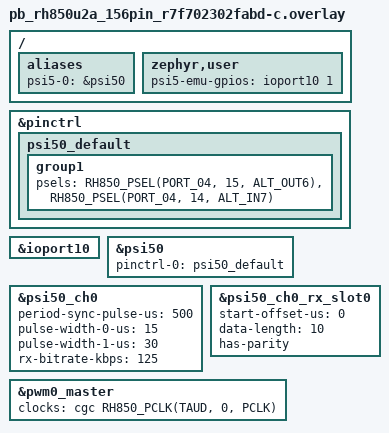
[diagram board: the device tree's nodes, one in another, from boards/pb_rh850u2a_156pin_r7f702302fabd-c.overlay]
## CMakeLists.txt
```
# SPDX-License-Identifier: Apache-2.0

cmake_minimum_required(VERSION 3.20.0)
find_package(Zephyr REQUIRED HINTS $ENV{ZEPHYR_BASE})
project(psi5_rx)

target_sources(app PRIVATE
  src/main.c
  src/psi5_emu.c
)
```

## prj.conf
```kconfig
CONFIG_ZTEST=y
CONFIG_PSI5=y
CONFIG_GPIO=y
CONFIG_LOG=y
```

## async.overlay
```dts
/*
 * Copyright (c) 2026 Renesas Electronics Corporation
 *
 * SPDX-License-Identifier: Apache-2.0
 */

/*
 * Scenario drivers.psi5.rx.async.data_frame (T22):
 * PSI5-A asynchronous mode on the test channel (no sync pulse, no TX).
 * Applied on top of boards/<board>.overlay via EXTRA_DTC_OVERLAY_FILE (testcase.yaml).
 * Driver: started in init (CHEN = 1), start_sync/stop_sync/send -> -ENOTSUP, slot@0 only.
 */
&psi50_ch0 {
	async-mode;
};
```

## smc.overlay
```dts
/*
 * Copyright (c) 2026 Renesas Electronics Corporation
 *
 * SPDX-License-Identifier: Apache-2.0
 */

/*
 * Enable serial message reception on the first RX slot.
 */
&psi50_ch0_rx_slot0 {
	has-smc;
};
```

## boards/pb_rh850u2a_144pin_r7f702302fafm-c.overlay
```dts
/*
 * Copyright (c) 2026 Renesas Electronics Corporation
 * SPDX-License-Identifier: Apache-2.0
 */

#include <zephyr/dt-bindings/gpio/gpio.h>

/ {
	aliases {
		psi5-0 = &psi50;
	};

	zephyr,user {
		psi5-emu-gpios = <&ioport10 1 GPIO_ACTIVE_HIGH>;
	};
};

&pinctrl {
	psi50_default: psi50_default {
		group1 {
			psels = <RH850_PSEL(PORT_04, 15, ALT_OUT6)>,
				<RH850_PSEL(PORT_04, 14, ALT_IN7)>;
		};
	};
};

&ioport10 {
	status = "okay";
};

&psi50 {
	pinctrl-0 = <&psi50_default>;
	pinctrl-names = "default";
	status = "okay";
};

&psi50_ch0 {
	period-sync-pulse-us = <500>;
	pulse-width-0-us = <15>;
	pulse-width-1-us = <30>;
	rx-bitrate-kbps = <125>;
	status = "okay";
};

&psi50_ch0_rx_slot0 {
	start-offset-us = <0>;
	data-length = <10>;
	has-parity;
	status = "okay";
};
```

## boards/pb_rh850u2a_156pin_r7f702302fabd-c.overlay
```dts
/*
 * Copyright (c) 2026 Renesas Electronics Corporation
 * SPDX-License-Identifier: Apache-2.0
 */

#include <zephyr/dt-bindings/gpio/gpio.h>

/ {
	aliases {
		psi5-0 = &psi50;
	};

	zephyr,user {
		psi5-emu-gpios = <&ioport10 1 GPIO_ACTIVE_HIGH>;
	};
};

&pinctrl {
	psi50_default: psi50_default {
		group1 {
			psels = <RH850_PSEL(PORT_04, 15, ALT_OUT6)>,
				<RH850_PSEL(PORT_04, 14, ALT_IN7)>;
		};
	};
};

&ioport10 {
	status = "okay";
};

&psi50 {
	pinctrl-0 = <&psi50_default>;
	pinctrl-names = "default";
	status = "okay";
};

&psi50_ch0 {
	period-sync-pulse-us = <500>;
	pulse-width-0-us = <15>;
	pulse-width-1-us = <30>;
	rx-bitrate-kbps = <125>;
	status = "okay";
};

&psi50_ch0_rx_slot0 {
	start-offset-us = <0>;
	data-length = <10>;
	has-parity;
	status = "okay";
};

&pwm0_master {
	clocks = <&cgc RH850_PCLK(TAUD, 0, PCLK)>;
	status = "okay";
};
```

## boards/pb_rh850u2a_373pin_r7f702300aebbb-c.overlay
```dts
/*
 * Copyright (c) 2026 Renesas Electronics Corporation
 * SPDX-License-Identifier: Apache-2.0
 */

#include <zephyr/dt-bindings/gpio/gpio.h>

/ {
	aliases {
		psi5-0 = &psi50;
	};

	zephyr,user {
		psi5-emu-gpios = <&ioport22 0 GPIO_ACTIVE_HIGH>;
	};
};

&pinctrl {
	psi50_default: psi50_default {
		group1 {
			psels = <RH850_PSEL(PORT_04, 15, ALT_OUT6)>,
				<RH850_PSEL(PORT_04, 14, ALT_IN7)>;
		};
	};
};

&ioport22 {
	status = "okay";
};

&psi50 {
	pinctrl-0 = <&psi50_default>;
	pinctrl-names = "default";
	status = "okay";
};

&psi50_ch0 {
	period-sync-pulse-us = <500>;
	pulse-width-0-us = <15>;
	pulse-width-1-us = <30>;
	rx-bitrate-kbps = <125>;
	status = "okay";
};

&psi50_ch0_rx_slot0 {
	start-offset-us = <0>;
	data-length = <10>;
	has-parity;
	status = "okay";
};

&pwm0_master {
	clocks = <&cgc RH850_PCLK(TAUD, 0, PCLK)>;
	status = "okay";
};
```

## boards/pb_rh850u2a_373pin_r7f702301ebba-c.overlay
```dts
/*
 * Copyright (c) 2026 Renesas Electronics Corporation
 * SPDX-License-Identifier: Apache-2.0
 */

#include <zephyr/dt-bindings/gpio/gpio.h>

/ {
	aliases {
		psi5-0 = &psi50;
	};

	zephyr,user {
		psi5-emu-gpios = <&ioport22 0 GPIO_ACTIVE_HIGH>;
	};
};

&pinctrl {
	psi50_default: psi50_default {
		group1 {
			psels = <RH850_PSEL(PORT_04, 15, ALT_OUT6)>,
				<RH850_PSEL(PORT_04, 14, ALT_IN7)>;
		};
	};
};

&ioport22 {
	status = "okay";
};

&psi50 {
	pinctrl-0 = <&psi50_default>;
	pinctrl-names = "default";
	status = "okay";
};

&psi50_ch0 {
	period-sync-pulse-us = <500>;
	pulse-width-0-us = <15>;
	pulse-width-1-us = <30>;
	rx-bitrate-kbps = <125>;
	status = "okay";
};

&psi50_ch0_rx_slot0 {
	start-offset-us = <0>;
	data-length = <10>;
	has-parity;
	status = "okay";
};
```

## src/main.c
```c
/*
 * Copyright (c) 2026 Renesas Electronics Corporation
 *
 * SPDX-License-Identifier: Apache-2.0
 */

#include <errno.h>
#include <stdbool.h>
#include <stdint.h>

#include <zephyr/device.h>
#include <zephyr/drivers/psi5/psi5.h>
#include <zephyr/kernel.h>
#include <zephyr/ztest.h>

#define PSI5_NODE          DT_ALIAS(psi5_0)
#define PSI5_CHANNEL       0U
#define PSI5_MAX_RX_BUFFER 1U
#define PSI5_RX_TIMEOUT    K_MSEC(100)
#define PSI5_NO_CB_WINDOW  K_MSEC(20)
#define PSI5_TX_TIMEOUT    K_MSEC(200)
#define PSI5_STOP_TIMEOUT  K_MSEC(200)

#define PSI5_EMU_DATA            0x1E7U
#define PSI5_EMU_RESTART_DATA    0x0ABU
#define PSI5_EMU_DATA_LEN        10U
#define PSI5_EMU_BAD_PARITY_DATA (0x3F3U | BIT(PSI5_EMU_DATA_LEN))
#define PSI5_EMU_BAD_PARITY_LEN  (PSI5_EMU_DATA_LEN + 1U)
#define PSI5_EMU_SMC_RESET_DATA  0x0F0U
#define PSI5_EMU_SMC_CRC         0x20U
#define PSI5_SMC_EXP_ID          0x55U
#define PSI5_SMC_EXP_DATA        0x3E1U
#define PSI5_SMC_TIMEOUT         K_MSEC(100)

#define PSI5_TX_DATA_FIT     0x3FU
#define PSI5_TX_DATA_OVER    0x40U
#define PSI5_TX_DATA_OVER_HI UINT64_C(0x100000000)

#define PSI5_SMC_SLOT_NODE DT_NODELABEL(psi50_ch0_rx_slot0)
#define PSI5_TEST_SMC      DT_PROP_OR(PSI5_SMC_SLOT_NODE, has_smc, 0)
#define PSI5_CH_NODE       DT_NODELABEL(psi50_ch0)
#define PSI5_TEST_ASYNC    DT_PROP_OR(PSI5_CH_NODE, async_mode, 0)

int psi5_emu_init(void);
int psi5_emu_send_frame(uint32_t data, uint8_t data_len, bool has_parity);
int psi5_emu_send_smc_pattern(uint8_t crc6);
int psi5_emu_send_frame_synced(uint32_t data, uint8_t data_len, bool has_parity);

static const struct device *const psi5_dev = DEVICE_DT_GET(PSI5_NODE);
static struct k_sem rx_sem;
static struct k_sem smc_sem;
static struct k_sem tx_sem;
static struct psi5_frame data_frame[PSI5_MAX_RX_BUFFER];
static struct psi5_frame serial_frame[PSI5_MAX_RX_BUFFER];

struct rx_result_data {
	uint32_t callback_count;
	uint32_t error_count;
	uint32_t num_frames;
	uint8_t channel;
};

struct smc_result_data {
	uint32_t callback_count;
	uint32_t error_count;
	uint32_t num_frames;
};

static volatile struct rx_result_data rx_result;
static volatile struct smc_result_data smc_result;
static volatile uint32_t tx_callback_count;
static volatile int tx_status[4];

static void reset_rx_result(void)
{
	rx_result = (struct rx_result_data){0};
	data_frame[0] = (struct psi5_frame){0};
	k_sem_reset(&rx_sem);
}

static void reset_smc_result(void)
{
	smc_result = (struct smc_result_data){0};
	serial_frame[0] = (struct psi5_frame){0};
	k_sem_reset(&smc_sem);
}

static void rx_data_frame_cb(const struct device *dev, uint8_t channel_id,
			     uint32_t num_frame, void *user_data)
{
	ARG_UNUSED(dev);
	ARG_UNUSED(user_data);

	rx_result.callback_count++;
	rx_result.error_count += (num_frame == 0U);
	rx_result.num_frames = num_frame;
	rx_result.channel = channel_id;
	k_sem_give(&rx_sem);
}

static void rx_serial_frame_cb(const struct device *dev, uint8_t channel_id,
			       uint32_t num_frame, void *user_data)
{
	ARG_UNUSED(dev);
	ARG_UNUSED(channel_id);
	ARG_UNUSED(user_data);

	smc_result.callback_count++;
	smc_result.error_count += (num_frame == 0U);
	smc_result.num_frames = num_frame;
	k_sem_give(&smc_sem);
}

static void tx_cb(const struct device *dev, uint8_t channel_id, int status,
		  void *user_data)
{
	uint32_t request = (uint32_t)(uintptr_t)user_data;

	ARG_UNUSED(dev);
	ARG_UNUSED(channel_id);

	tx_callback_count++;
	if (request < ARRAY_SIZE(tx_status)) {
		tx_status[request] = status;
	}
	k_sem_give(&tx_sem);
}

static struct psi5_rx_callback_config serial_cb_cfg = {
	.callback = rx_serial_frame_cb,
	.frame = serial_frame,
	.max_num_frame = ARRAY_SIZE(serial_frame),
};

static struct psi5_rx_callback_config data_cb_cfg = {
	.callback = rx_data_frame_cb,
	.frame = data_frame,
	.max_num_frame = ARRAY_SIZE(data_frame),
};

static struct psi5_rx_callback_configs callback_configs = {
	.serial_frame = &serial_cb_cfg,
	.data_frame = &data_cb_cfg,
};

static int send_frame(uint32_t data, uint8_t data_len, bool has_parity)
{
	if (PSI5_TEST_ASYNC) {
		return psi5_emu_send_frame(data, data_len, has_parity);
	}
	return psi5_emu_send_frame_synced(data, data_len, has_parity);
}

/*
 * The driver does not wait: psi5_stop_sync() returns -EBUSY while a TX frame is still
 * in the TX buffer. The application retries until the frame has been sent.
 */
static int stop_sync_wait(void)
{
	k_timepoint_t end = sys_timepoint_calc(PSI5_STOP_TIMEOUT);
	int ret;

	do {
		ret = psi5_stop_sync(psi5_dev, PSI5_CHANNEL);
		if (ret != -EBUSY) {
			return ret;
		}
		k_msleep(1);
	} while (!sys_timepoint_expired(end));

	return ret;
}

static void *psi5_rx_setup(void)
{
	int ret;

	zassert_true(device_is_ready(psi5_dev), "PSI5 device is not ready");
	k_sem_init(&rx_sem, 0, 1);
	k_sem_init(&smc_sem, 0, 1);
	k_sem_init(&tx_sem, 0, 4);

	zassert_ok(psi5_emu_init(), "Failed to initialize PSI5 emulator");
	zassert_ok(psi5_register_callback(psi5_dev, PSI5_CHANNEL, callback_configs),
		   "Failed to register callbacks");

	ret = psi5_start_sync(psi5_dev, PSI5_CHANNEL);
	if (PSI5_TEST_ASYNC) {
		zassert_equal(ret, -ENOTSUP, "start_sync returned %d", ret);
	} else {
		zassert_ok(ret, "start_sync returned %d", ret);
	}

	return NULL;
}

static void psi5_rx_teardown(void *fixture)
{
	int ret;

	ARG_UNUSED(fixture);
	if (PSI5_TEST_ASYNC) {
		ret = psi5_stop_sync(psi5_dev, PSI5_CHANNEL);
		zassert_equal(ret, -ENOTSUP, "stop_sync returned %d", ret);
	} else {
		ret = stop_sync_wait();
		zassert_ok(ret, "stop_sync returned %d", ret);
	}
}

ZTEST(psi5_rx, test_receive_reference_data_frame)
{
	reset_rx_result();
	zassert_ok(send_frame(PSI5_EMU_DATA, PSI5_EMU_DATA_LEN, true),
		   "Failed to send reference frame");
	zassert_ok(k_sem_take(&rx_sem, PSI5_RX_TIMEOUT), "RX callback timeout");

	zassert_equal(rx_result.num_frames, 1U, "Expected one frame");
	zassert_equal(rx_result.channel, PSI5_CHANNEL, "Unexpected channel");
	zassert_equal(data_frame[0].type, PSI5_DATA_FRAME, "Unexpected type");
	zassert_equal(data_frame[0].data, PSI5_EMU_DATA, "Unexpected data");
	zassert_equal(data_frame[0].slot_number, 0U, "Unexpected slot");
}

ZTEST(psi5_rx, test_rx_frame_error)
{
	reset_rx_result();
	zassert_ok(send_frame(PSI5_EMU_BAD_PARITY_DATA, PSI5_EMU_BAD_PARITY_LEN, false),
		   "Failed to send bad-parity frame");
	zassert_ok(k_sem_take(&rx_sem, PSI5_RX_TIMEOUT), "Error callback timeout");
	k_msleep(10);

	zassert_equal(rx_result.num_frames, 0U, "Bad frame reported as valid");
	zassert_equal(rx_result.error_count, 1U, "Expected one error callback");
	zassert_equal(rx_result.callback_count, 1U, "Unexpected duplicate callback");

	reset_rx_result();
	zassert_ok(send_frame(PSI5_EMU_DATA, PSI5_EMU_DATA_LEN, true),
		   "Failed to send recovery frame");
	zassert_ok(k_sem_take(&rx_sem, PSI5_RX_TIMEOUT), "Recovery callback timeout");
	zassert_equal(rx_result.num_frames, 1U, "Receiver did not recover");
	zassert_equal(data_frame[0].data, PSI5_EMU_DATA, "Unexpected recovery data");
}

ZTEST(psi5_rx, test_rx_serial_message)
{
	if (!PSI5_TEST_SMC || !PSI5_TEST_ASYNC) {
		ztest_test_skip();
	}

	reset_rx_result();
	zassert_ok(send_frame(PSI5_EMU_SMC_RESET_DATA, PSI5_EMU_DATA_LEN, true),
		   "Failed to send SMC reset frame");
	(void)k_sem_take(&rx_sem, PSI5_RX_TIMEOUT);

	reset_rx_result();
	reset_smc_result();
	zassert_ok(psi5_emu_send_smc_pattern(PSI5_EMU_SMC_CRC),
		   "Failed to send SMC pattern");
	zassert_ok(k_sem_take(&smc_sem, PSI5_SMC_TIMEOUT), "SMC callback timeout");
	k_msleep(10);

	zassert_equal(smc_result.error_count, 0U, "SMC error reported");
	zassert_equal(smc_result.callback_count, 1U, "Unexpected SMC callback count");
	zassert_equal(smc_result.num_frames, 1U, "Expected one message");
	zassert_equal(serial_frame[0].type, PSI5_SERIAL_FRAME_8_BIT_ID, "Unexpected type");
	zassert_equal(serial_frame[0].serial.id, PSI5_SMC_EXP_ID, "Unexpected ID");
	zassert_equal(serial_frame[0].serial.data, PSI5_SMC_EXP_DATA, "Unexpected data");
	zassert_equal(serial_frame[0].crc, PSI5_EMU_SMC_CRC, "Unexpected CRC");
	zassert_equal(serial_frame[0].slot_number, 0U, "Unexpected slot");
	zassert_equal(rx_result.error_count, 0U, "Data error during SMC");
}

ZTEST(psi5_rx, test_rx_stop_start)
{
	int ret;

	if (PSI5_TEST_ASYNC) {
		ztest_test_skip();
	}

	zassert_ok(psi5_stop_sync(psi5_dev, PSI5_CHANNEL), "stop_sync failed");
	reset_rx_result();
	zassert_ok(psi5_emu_send_frame(PSI5_EMU_RESTART_DATA, PSI5_EMU_DATA_LEN, true),
		   "Failed to send while stopped");
	ret = k_sem_take(&rx_sem, PSI5_NO_CB_WINDOW);
	zassert_equal(ret, -EAGAIN, "Callback received while stopped");
	zassert_equal(rx_result.callback_count, 0U, "Unexpected callback while stopped");

	zassert_ok(psi5_start_sync(psi5_dev, PSI5_CHANNEL), "restart failed");
	reset_rx_result();
	zassert_ok(send_frame(PSI5_EMU_RESTART_DATA, PSI5_EMU_DATA_LEN, true),
		   "Failed to send after restart");
	zassert_ok(k_sem_take(&rx_sem, PSI5_RX_TIMEOUT), "RX timeout after restart");
	zassert_equal(rx_result.num_frames, 1U, "Expected one frame");
	zassert_equal(data_frame[0].data, PSI5_EMU_RESTART_DATA, "Stale or invalid data");
}

ZTEST(psi5_rx, test_async_mode)
{
	if (!PSI5_TEST_ASYNC) {
		ztest_test_skip();
	}

	zassert_equal(psi5_start_sync(psi5_dev, PSI5_CHANNEL), -ENOTSUP,
		      "start_sync must be unsupported");
	zassert_equal(psi5_stop_sync(psi5_dev, PSI5_CHANNEL), -ENOTSUP,
		      "stop_sync must be unsupported");
	zassert_equal(psi5_send(psi5_dev, PSI5_CHANNEL, 0x2AU, K_NO_WAIT, tx_cb, NULL),
		      -ENOTSUP, "send must be unsupported");

	reset_rx_result();
	zassert_ok(send_frame(PSI5_EMU_DATA, PSI5_EMU_DATA_LEN, true), "Send failed");
	zassert_ok(k_sem_take(&rx_sem, PSI5_RX_TIMEOUT), "Async RX timeout");
	zassert_equal(rx_result.num_frames, 1U, "Expected one frame");
	zassert_equal(data_frame[0].data, PSI5_EMU_DATA, "Unexpected data");
}

ZTEST(psi5_rx, test_tx_data_width)
{
	int ret;

	if (PSI5_TEST_ASYNC) {
		ztest_test_skip();
	}

	tx_callback_count = 0U;
	for (uint32_t i = 0U; i < ARRAY_SIZE(tx_status); i++) {
		tx_status[i] = 1;
	}
	k_sem_reset(&tx_sem);

	zassert_ok(psi5_send(psi5_dev, PSI5_CHANNEL, PSI5_TX_DATA_FIT,
			     PSI5_TX_TIMEOUT, tx_cb, (void *)0U), "Valid send failed");
	zassert_ok(k_sem_take(&tx_sem, PSI5_TX_TIMEOUT), "TX callback timeout");
	zassert_equal(tx_status[0], 0, "Unexpected TX status");

	zassert_equal(psi5_send(psi5_dev, PSI5_CHANNEL, PSI5_TX_DATA_OVER,
				K_NO_WAIT, tx_cb, (void *)1U), -EMSGSIZE,
		      "Oversized data was not rejected");
	zassert_equal(psi5_send(psi5_dev, PSI5_CHANNEL, PSI5_TX_DATA_OVER_HI,
				K_NO_WAIT, tx_cb, (void *)1U), -EMSGSIZE,
		      "High-bit data was not rejected");
	ret = k_sem_take(&tx_sem, PSI5_NO_CB_WINDOW);
	zassert_equal(ret, -EAGAIN, "Callback received for rejected data");

	zassert_ok(psi5_send(psi5_dev, PSI5_CHANNEL, 0x01U, PSI5_TX_TIMEOUT,
			     tx_cb, (void *)1U), "Send after error failed");
	zassert_ok(k_sem_take(&tx_sem, PSI5_TX_TIMEOUT), "TX callback timeout");

	zassert_ok(stop_sync_wait(), "stop_sync failed");
	zassert_equal(psi5_send(psi5_dev, PSI5_CHANNEL, PSI5_TX_DATA_OVER,
				K_NO_WAIT, tx_cb, (void *)2U), -ENETDOWN,
		      "Stopped state must take priority");
	zassert_ok(psi5_start_sync(psi5_dev, PSI5_CHANNEL), "restart failed");
}

ZTEST(psi5_rx, test_tx_rx_concurrent)
{
	if (PSI5_TEST_ASYNC) {
		ztest_test_skip();
	}

	tx_callback_count = 0U;
	for (uint32_t i = 0U; i < ARRAY_SIZE(tx_status); i++) {
		tx_status[i] = 1;
	}
	k_sem_reset(&tx_sem);
	reset_rx_result();

	zassert_ok(psi5_send(psi5_dev, PSI5_CHANNEL, 0x15U, K_NO_WAIT,
			     tx_cb, (void *)0U), "Concurrent TX failed");
	zassert_ok(send_frame(PSI5_EMU_DATA, PSI5_EMU_DATA_LEN, true),
		   "Concurrent RX frame failed");
	zassert_ok(k_sem_take(&rx_sem, PSI5_RX_TIMEOUT), "Concurrent RX timeout");
	zassert_equal(data_frame[0].data, PSI5_EMU_DATA, "Unexpected RX data");
	zassert_ok(k_sem_take(&tx_sem, PSI5_TX_TIMEOUT), "Concurrent TX timeout");
	zassert_equal(tx_status[0], 0, "Unexpected TX status");

	/* Back-to-back request: tx_sem was released by the previous completion */
	zassert_ok(psi5_send(psi5_dev, PSI5_CHANNEL, 0x2AU, K_NO_WAIT,
			     tx_cb, (void *)1U), "Second request failed");
	zassert_ok(k_sem_take(&tx_sem, PSI5_TX_TIMEOUT), "Second request timeout");
	zassert_equal(tx_status[1], 0, "Unexpected second TX status");
}

ZTEST_SUITE(psi5_rx, NULL, psi5_rx_setup, NULL, NULL, psi5_rx_teardown);
```

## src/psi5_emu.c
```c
/*
 * Copyright (c) 2026 Renesas Electronics Corporation
 *
 * SPDX-License-Identifier: Apache-2.0
 */

/* PSI5 sensor emulator for hardware tests. */

#include <errno.h>
#include <stdbool.h>
#include <stdint.h>

#include <zephyr/device.h>
#include <zephyr/drivers/clock_control.h>
#include <zephyr/drivers/gpio.h>
#include <zephyr/irq.h>
#include <zephyr/kernel.h>
#include <zephyr/logging/log.h>
#include <zephyr/sys/atomic.h>

#include <soc.h>
#include "bsp_api.h"

LOG_MODULE_REGISTER(psi5_emu, LOG_LEVEL_INF);

#define PSI5_EMU_HALF_BIT_US       4U
#define PSI5_EMU_START_BITS        2U
#define PSI5_EMU_MAX_DATA_BITS     28U
#define PSI5_EMU_BUF_SIZE          (((PSI5_EMU_START_BITS + PSI5_EMU_MAX_DATA_BITS + 1U) * 2U) + 1U)
#define PSI5_EMU_SEND_TIMEOUT_MS   50U
#define PSI5_EMU_END               0xFFU
#define PSI5_EMU_SMC_FRAMES        18U
#define PSI5_EMU_SMC_CRC_FRAMES    6U
#define PSI5_EMU_SMC_DATA_LEN      10U
#define PSI5_EMU_SMC_IDLE_US       8U
#define PSI5_EMU_SYNC_DELAY_US  20U
#define PSI5_EMU_SYNC_TIMEOUT_US  2000U
#define PSI5_EMU_REG            ((R_PSI50_Type *)DT_REG_ADDR(DT_ALIAS(psi5_0)))

#define PSI5_EMU_TAUD_NODE DT_NODELABEL(pwm0_ch0)
BUILD_ASSERT(DT_NODE_EXISTS(PSI5_EMU_TAUD_NODE), "pwm0_ch0 node not found");
BUILD_ASSERT(DT_PROP(PSI5_EMU_TAUD_NODE, unit) == 0, "Emulator uses TAUD0 only");
BUILD_ASSERT(DT_PROP(PSI5_EMU_TAUD_NODE, channel) == 0,
	     "PSI5 emulator ISR requires TAUD0 channel 0");
BUILD_ASSERT(!IS_ENABLED(CONFIG_PWM_RENESAS_RH850),
	     "TAUD0 ch0 is owned by the PWM driver; disable CONFIG_PWM for psi5_rx");

#define PSI5_EMU_TAUD_CH       DT_PROP(PSI5_EMU_TAUD_NODE, channel)
#define PSI5_EMU_TAUD_IRQ      DT_IRQN(PSI5_EMU_TAUD_NODE)
#define PSI5_EMU_IRQ_PRIO      0
#define PSI5_EMU_TAUD_CLK_ID   DT_CLOCKS_CELL(PSI5_EMU_TAUD_NODE, clk_id)
#define PSI5_EMU_TAUD_CH_MASK  ((uint16_t)(1U << PSI5_EMU_TAUD_CH))
#define PSI5_EMU_TAUD_CMOR     0x0001U

#ifdef BSP_CFG_CLOCK_CLK_HSB_HZ
#define PSI5_EMU_CLK_HZ BSP_CFG_CLOCK_CLK_HSB_HZ
#else
#define PSI5_EMU_CLK_HZ 80000000U
#endif

#define PSI5_EMU_PERIOD_COUNTS \
	(PSI5_EMU_HALF_BIT_US * (PSI5_EMU_CLK_HZ / 1000000U))

BUILD_ASSERT(PSI5_EMU_PERIOD_COUNTS > 0U, "Invalid TAUD period");
BUILD_ASSERT(PSI5_EMU_PERIOD_COUNTS <= UINT16_MAX, "TAUD period does not fit CDR");

static const struct device *const taud_clk_dev =
	DEVICE_DT_GET(DT_CLOCKS_CTLR(PSI5_EMU_TAUD_NODE));
static const struct gpio_dt_spec emu_gpio =
	GPIO_DT_SPEC_GET(DT_PATH(zephyr_user), psi5_emu_gpios);

static const uint16_t psi5_emu_smc_data[PSI5_EMU_SMC_FRAMES] = {
	0x3F2, 0x3F2, 0x3F2, 0x3F2, 0x3F2, 0x3F2,
	0x0F0, 0x0F0, 0x3F1, 0x3F3, 0x3F1, 0x3F3,
	0x0F1, 0x3F0, 0x3F2, 0x3F0, 0x3F2, 0x0F1,
};

static uint8_t psi5_emu_buf[PSI5_EMU_BUF_SIZE];
static atomic_t psi5_emu_busy;
static const uint8_t *volatile psi5_emu_pattern;
static volatile uint32_t psi5_emu_idx;

static inline void psi5_emu_timer_stop(void)
{
	R_TAUD0->TAUDnTT = PSI5_EMU_TAUD_CH_MASK;
}

static void psi5_emu_isr(const void *arg)
{
	const uint8_t *pattern = psi5_emu_pattern;
	uint8_t level;

	ARG_UNUSED(arg);
	R_BSP_IrqStatusClear((IRQn_Type)PSI5_EMU_TAUD_IRQ);

	if (pattern == NULL) {
		return;
	}

	level = pattern[psi5_emu_idx];
	if (level == PSI5_EMU_END) {
		psi5_emu_timer_stop();
		(void)gpio_pin_set_dt(&emu_gpio, 0);
		psi5_emu_pattern = NULL;
		return;
	}

	(void)gpio_pin_set_dt(&emu_gpio, level);
	psi5_emu_idx++;
}

int psi5_emu_init(void)
{
	static bool initialized;
	int ret;

	if (initialized) {
		return 0;
	}

	if (!gpio_is_ready_dt(&emu_gpio)) {
		return -ENODEV;
	}

	ret = gpio_pin_configure_dt(&emu_gpio, GPIO_OUTPUT_INACTIVE);
	if (ret != 0) {
		return ret;
	}

	if (!device_is_ready(taud_clk_dev)) {
		return -ENODEV;
	}

	ret = clock_control_on(taud_clk_dev,
		(clock_control_subsys_t)(uintptr_t)PSI5_EMU_TAUD_CLK_ID);
	if (ret < 0) {
		return ret;
	}

	psi5_emu_timer_stop();
	R_TAUD0->TAUDnTPS_b.TAUDnPRS0 = 0U;
	R_TAUD0->TAUDnCMOR[PSI5_EMU_TAUD_CH].TAUDnCMOR = PSI5_EMU_TAUD_CMOR;
	R_TAUD0->TAUDnCDR[PSI5_EMU_TAUD_CH].TAUDnCDR =
		(uint16_t)(PSI5_EMU_PERIOD_COUNTS - 1U);
	R_TAUD0->TAUDnTOE &= (uint16_t)~PSI5_EMU_TAUD_CH_MASK;

	IRQ_CONNECT(PSI5_EMU_TAUD_IRQ, PSI5_EMU_IRQ_PRIO, psi5_emu_isr, NULL, 0);
	R_BSP_IrqStatusClear((IRQn_Type)PSI5_EMU_TAUD_IRQ);
	irq_enable(PSI5_EMU_TAUD_IRQ);

	atomic_clear(&psi5_emu_busy);
	initialized = true;

	LOG_INF("PSI5 emulator ready: TAUD0 ch%d, half-bit %u us",
		PSI5_EMU_TAUD_CH, PSI5_EMU_HALF_BIT_US);
	return 0;
}

int psi5_emu_send_pattern(const uint8_t *pattern)
{
	uint32_t start_cycles;
	uint32_t timeout_cycles;
	int ret = 0;

	if (pattern == NULL) {
		return -EINVAL;
	}

	if (!atomic_cas(&psi5_emu_busy, 0, 1)) {
		return -EBUSY;
	}

	psi5_emu_idx = 0U;
	psi5_emu_pattern = pattern;
	(void)gpio_pin_set_dt(&emu_gpio, 0);

	R_BSP_IrqStatusClear((IRQn_Type)PSI5_EMU_TAUD_IRQ);
	R_TAUD0->TAUDnTS = PSI5_EMU_TAUD_CH_MASK;

	start_cycles = k_cycle_get_32();
	timeout_cycles = k_ms_to_cyc_ceil32(PSI5_EMU_SEND_TIMEOUT_MS);
	while (psi5_emu_pattern != NULL) {
		if ((k_cycle_get_32() - start_cycles) > timeout_cycles) {
			psi5_emu_timer_stop();
			psi5_emu_pattern = NULL;
			(void)gpio_pin_set_dt(&emu_gpio, 0);
			ret = -ETIMEDOUT;
			break;
		}
	}

	atomic_clear(&psi5_emu_busy);
	return ret;
}

int psi5_emu_send_frame(uint32_t data, uint8_t data_len, bool has_parity)
{
	uint32_t idx = 0U;
	uint32_t ones = 0U;

	if ((data_len == 0U) || (data_len > PSI5_EMU_MAX_DATA_BITS)) {
		return -EINVAL;
	}

	for (uint32_t i = 0U; i < PSI5_EMU_START_BITS; i++) {
		psi5_emu_buf[idx++] = 0U;
		psi5_emu_buf[idx++] = 1U;
	}

	for (uint8_t i = 0U; i < data_len; i++) {
		uint8_t bit = (uint8_t)((data >> i) & 1U);

		ones += bit;
		psi5_emu_buf[idx++] = bit;
		psi5_emu_buf[idx++] = (uint8_t)!bit;
	}

	if (has_parity) {
		uint8_t parity = (uint8_t)(ones & 1U);

		psi5_emu_buf[idx++] = parity;
		psi5_emu_buf[idx++] = (uint8_t)!parity;
	}

	psi5_emu_buf[idx] = PSI5_EMU_END;
	return psi5_emu_send_pattern(psi5_emu_buf);
}

int psi5_emu_send_smc_pattern(uint8_t crc6)
{
	for (uint32_t frame = 0U; frame < PSI5_EMU_SMC_FRAMES; frame++) {
		uint32_t data = psi5_emu_smc_data[frame];
		int ret;

		if (frame < PSI5_EMU_SMC_CRC_FRAMES) {
			data |= ((uint32_t)crc6 >>
				 (PSI5_EMU_SMC_CRC_FRAMES - 1U - frame)) & 1U;
		}

		ret = psi5_emu_send_frame(data, PSI5_EMU_SMC_DATA_LEN, true);
		if (ret != 0) {
			return ret;
		}
		k_busy_wait(PSI5_EMU_SMC_IDLE_US);
	}

	return 0;
}

int psi5_emu_send_frame_synced(uint32_t data, uint8_t data_len, bool has_parity)
{
	uint32_t guard = PSI5_EMU_SYNC_TIMEOUT_US;

	PSI5_EMU_REG->PSI5nTXSTCLR = R_PSI50_PSI5nTXSTCLR_SYNCEDCLR_Msk;
	while ((PSI5_EMU_REG->PSI5nTXST & R_PSI50_PSI5nTXST_SYNCED_Msk) == 0U) {
		if (--guard == 0U) {
			return -ETIMEDOUT;
		}
		k_busy_wait(1);
	}
	k_busy_wait(PSI5_EMU_SYNC_DELAY_US);

	return psi5_emu_send_frame(data, data_len, has_parity);
}
```
